# STM32U5Gx register map
File version: 1.0
CPU: CM33 r0p1, little endian, MPU, FPU, 4 interrupt priority bits
Registers are 32-bit, read-write, reset 0x0 unless marked. A register's access mark holds for its fields unless they carry their own. Offsets are from the block's base; [hi:lo] are bit positions; {n}, {i} and the like mark numbered series.

## DBGMCU — MCU debug component
Base 0xE0044000
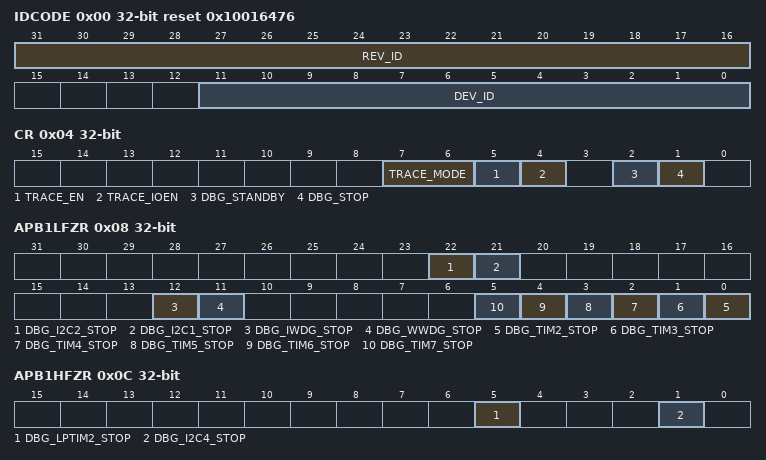
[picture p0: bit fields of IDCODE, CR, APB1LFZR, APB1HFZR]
0x00 IDCODE ro reset 0x10016476 — DBGMCU_IDCODE
  [31:16] REV_ID — Revision
  [11:0] DEV_ID — Device dentification
0x04 CR — Debug MCU configuration register
  [7:6] TRACE_MODE — Trace pin assignment control
  [5] TRACE_EN — trace port and clock enable
  [4] TRACE_IOEN — Trace pin assignment control
  [2] DBG_STANDBY — Debug Standby mode
  [1] DBG_STOP — Debug Stop mode
0x08 APB1LFZR — Debug MCU APB1L peripheral freeze register
  [22] DBG_I2C2_STOP — I2C2 SMBUS timeout stop in debug
  [21] DBG_I2C1_STOP — I2C1 SMBUS timeout stop in debug
  [12] DBG_IWDG_STOP — Independent watchdog counter stop in debug
  [11] DBG_WWDG_STOP — Window watchdog counter stop in debug
  [n-2] DBG_TIM{n}_STOP (n=2..7) — TIM{n} stop in debug
0x0C APB1HFZR — Debug MCU APB1H peripheral freeze register
  [5] DBG_LPTIM2_STOP — LPTIM2 stop in debug
  [1] DBG_I2C4_STOP — I2C4 stop in debug
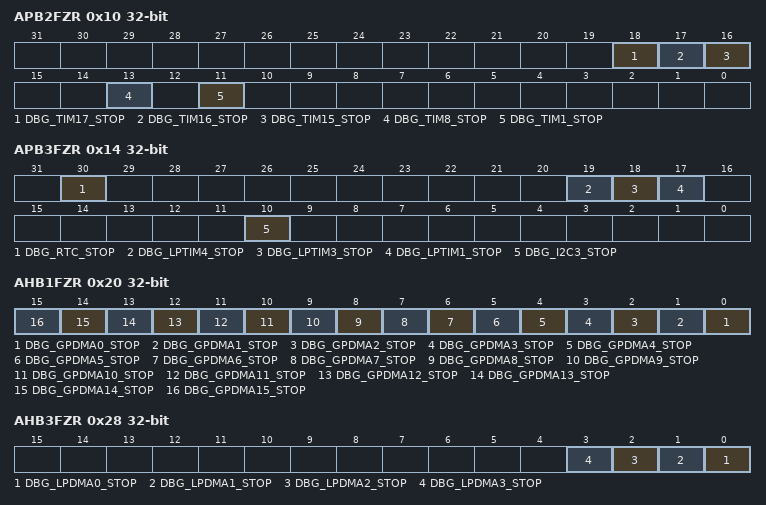
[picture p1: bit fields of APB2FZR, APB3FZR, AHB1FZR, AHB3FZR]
0x10 APB2FZR — Debug MCU APB2 peripheral freeze register
  [18] DBG_TIM17_STOP
  [17] DBG_TIM16_STOP — TIM16 counter stopped when core is halted
  [16] DBG_TIM15_STOP — TIM15 counter stopped when core is halted
  [13] DBG_TIM8_STOP — TIM8 stop in debug
  [11] DBG_TIM1_STOP — TIM1 counter stopped when core is halted
0x14 APB3FZR — Debug MCU APB3 peripheral freeze register
  [30] DBG_RTC_STOP — RTC stop in debug
  [19] DBG_LPTIM4_STOP — LPTIM4 stop in debug
  [18] DBG_LPTIM3_STOP — LPTIM3 stop in debug
  [17] DBG_LPTIM1_STOP — LPTIM1 stop in debug
  [10] DBG_I2C3_STOP — I2C3 stop in debug
0x20 AHB1FZR — Debug MCU AHB1 peripheral freeze register
  [n] DBG_GPDMA{n}_STOP (n=0..15) — GPDMA channel {n} stop in debug
0x28 AHB3FZR — Debug MCU AHB3 peripheral freeze register
  [n] DBG_LPDMA{n}_STOP (n=0..3) — LPDMA channel {n} stop in debug
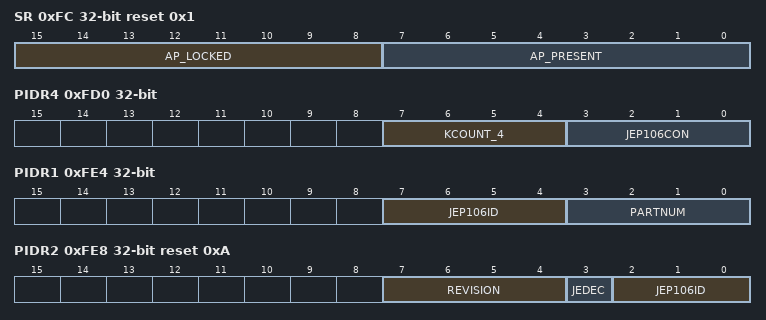
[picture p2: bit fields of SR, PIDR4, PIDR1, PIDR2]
0xFC SR ro reset 0x1 — DBGMCU status register
  [15:8] AP_LOCKED, [7:0] AP_PRESENT
0x100 DBGMCU_DBG_AUTH_HOST ro — DBGMCU debug host authentication register
  [31:0] AUTH_KEY
0x104 DBG_AUTH_DEVICE ro — DBGMCU debug device authentication register
  [15:0] AUTH_ID
0xFD0 PIDR4 ro — Debug MCU CoreSight peripheral identity register 4
  [7:4] KCOUNT_4 — register file size
  [3:0] JEP106CON — JEP106 continuation code
0xFE0 PIDR0 ro — Debug MCU CoreSight peripheral identity register 0
  [7:0] PARTNUM — part number bits [7:0]
0xFE4 PIDR1 ro — Debug MCU CoreSight peripheral identity register 1
  [7:4] JEP106ID — JEP106 identity code bits [3:0]
  [3:0] PARTNUM — part number bits [11:8]
0xFE8 PIDR2 ro reset 0xA — Debug MCU CoreSight peripheral identity register 2
  [7:4] REVISION — component revision number
  [3] JEDEC — JEDEC assigned value
  [2:0] JEP106ID — JEP106 identity code bits [6:4]
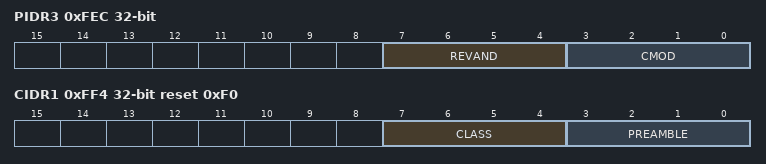
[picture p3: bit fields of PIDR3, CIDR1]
0xFEC PIDR3 ro — Debug MCU CoreSight peripheral identity register 3
  [7:4] REVAND — metal fix version
  [3:0] CMOD — customer modified
0xFF0 CIDR0 ro reset 0xD — Debug MCU CoreSight component identity register 0
  [7:0] PREAMBLE — component identification bits [7:0]
0xFF4 CIDR1 ro reset 0xF0 — Debug MCU CoreSight component identity register 1
  [7:4] CLASS — component identification bits [15:12] - component class
  [3:0] PREAMBLE — component identification bits [11:8]
0xFF8 CIDR2 ro reset 0x5 — Debug MCU CoreSight component identity register 2
  [7:0] PREAMBLE — component identification bits [23:16]
0xFFC CIDR3 ro reset 0xB1 — Debug MCU CoreSight component identity register 3
  [7:0] PREAMBLE — component identification bits [31:24]

## DCACHE1
Base 0x40031400
Same registers: DCACHE2 0x40031800, SEC_DCACHE1 0x50031400, SEC_DCACHE2 0x50031800
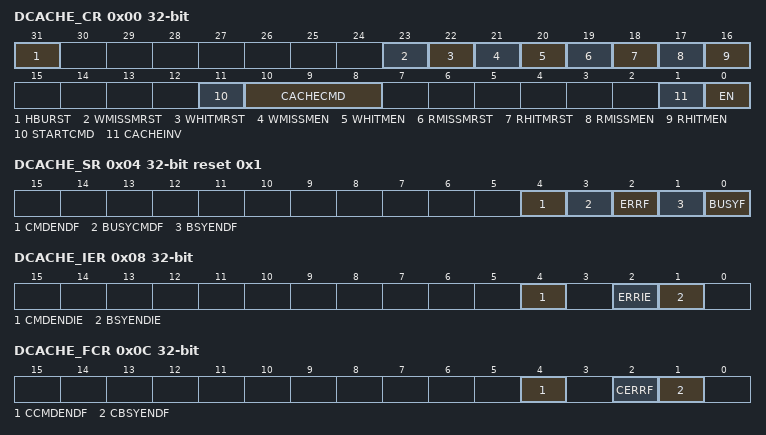
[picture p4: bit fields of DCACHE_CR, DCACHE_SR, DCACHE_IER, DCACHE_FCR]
0x00 DCACHE_CR access per field — DCACHE control register
  [31] HBURST rw, [23] WMISSMRST rw, [22] WHITMRST rw, [21] WMISSMEN rw, [20] WHITMEN rw, [19] RMISSMRST rw, [18] RHITMRST rw, [17] RMISSMEN rw, [16] RHITMEN rw, [11] STARTCMD wo, [10:8] CACHECMD rw, [1] CACHEINV wo, [0] EN rw
0x04 DCACHE_SR ro reset 0x1 — DCACHE status register
  [4] CMDENDF, [3] BUSYCMDF, [2] ERRF, [1] BSYENDF, [0] BUSYF
0x08 DCACHE_IER — DCACHE interrupt enable register
  [4] CMDENDIE, [2] ERRIE, [1] BSYENDIE
0x0C DCACHE_FCR wo — DCACHE flag clear register
  [4] CCMDENDF, [2] CERRF, [1] CBSYENDF
0x10 DCACHE_RHMONR ro — DCACHE read-hit monitor register
  [31:0] RHITMON
0x14 DCACHE_RMMONR ro — DCACHE read-miss monitor register
  [15:0] MRISSMON — RMISSMON
0x20 DCACHE_WHMONR ro — write-hit monitor register
  [31:0] WHITMON
0x24 DCACHE_WMMONR ro — write-miss monitor register
  [15:0] WMISSMON
0x28 DCACHE_CMDRSADDRR — command range start address register
  [31:4] CMDSTARTADDR
0x2C DCACHE_CMDREADDRR — command range start address register
  [31:4] CMDENDADDR
